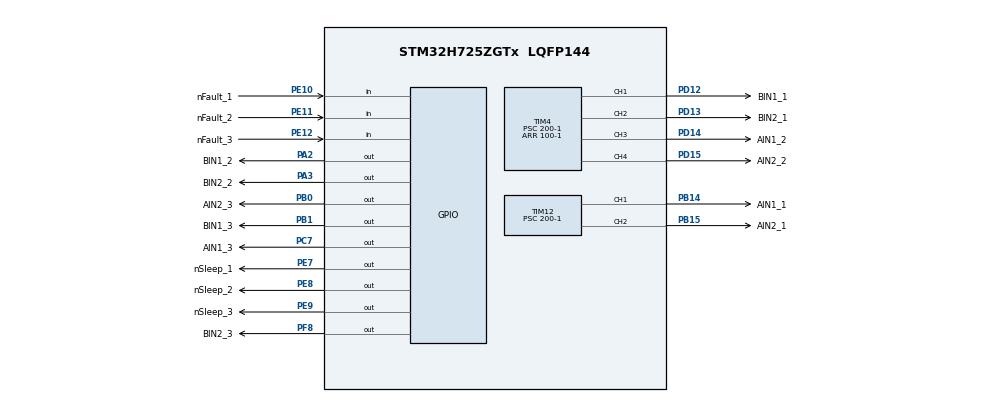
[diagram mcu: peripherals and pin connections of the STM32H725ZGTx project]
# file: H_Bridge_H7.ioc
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Mcu.Family=STM32H7
Mcu.Name=STM32H725ZGTx
Mcu.Package=LQFP144
NVIC.PriorityGroup=NVIC_PRIORITYGROUP_4
NVIC.TIM5_IRQn=true\:0\:0\:false\:false\:true\:true\:true\:true
PA2.GPIO_Label=BIN1_2
PA2.Signal=GPIO_Output
PA3.GPIO_Label=BIN2_2
PA3.Signal=GPIO_Output
PB0.GPIO_Label=AIN2_3
PB0.Signal=GPIO_Output
PB1.GPIO_Label=BIN1_3
PB1.Signal=GPIO_Output
PB14.GPIO_Label=AIN1_1
PB14.Signal=S_TIM12_CH1
PB15.GPIO_Label=AIN2_1
PB15.Signal=S_TIM12_CH2
PC7.GPIO_Label=AIN1_3
PC7.Signal=GPIO_Output
PD12.GPIO_Label=BIN1_1
PD12.Signal=S_TIM4_CH1
PD13.GPIO_Label=BIN2_1
PD13.Signal=S_TIM4_CH2
PD14.GPIO_Label=AIN1_2
PD14.Signal=S_TIM4_CH3
PD15.GPIO_Label=AIN2_2
PD15.Signal=S_TIM4_CH4
PE10.GPIO_Label=nFault_1
PE10.Signal=GPIO_Input
PE11.GPIO_Label=nFault_2
PE11.Signal=GPIO_Input
PE12.GPIO_Label=nFault_3
PE12.Signal=GPIO_Input
PE7.GPIO_Label=nSleep_1
PE7.Signal=GPIO_Output
PE8.GPIO_Label=nSleep_2
PE8.Signal=GPIO_Output
PE9.GPIO_Label=nSleep_3
PE9.Signal=GPIO_Output
PF8.GPIO_Label=BIN2_3
PF8.Signal=GPIO_Output
PH0-OSC_IN.Mode=HSE-External-Oscillator
PH0-OSC_IN.Signal=RCC_OSC_IN
PH1-OSC_OUT.Mode=HSE-External-Oscillator
PH1-OSC_OUT.Signal=RCC_OSC_OUT
ProjectManager.HeapSize=0x200
ProjectManager.StackSize=0x400
ProjectManager.TargetToolchain=STM32CubeIDE
RCC.ADCFreq_Value=50390625
RCC.APB1Freq_Value=100000000
RCC.APB2Freq_Value=100000000
RCC.APB3Freq_Value=100000000
RCC.APB4Freq_Value=100000000
RCC.CortexFreq_Value=200000000
RCC.D1PPRE=RCC_APB3_DIV2
RCC.D2PPRE1=RCC_APB1_DIV2
RCC.D2PPRE2=RCC_APB2_DIV2
RCC.D3PPRE=RCC_APB4_DIV2
RCC.DIVM1=2
RCC.DIVN1=16
RCC.DIVP1=1
RCC.HCLKFreq_Value=200000000
RCC.PLL2FRACN=0
RCC.PLL3FRACN=0
RCC.PLLFRACN=0
RCC.PLLSourceVirtual=RCC_PLLSOURCE_HSE
RCC.SYSCLKFreq_VALUE=200000000
RCC.SYSCLKSource=RCC_SYSCLKSOURCE_PLLCLK
RCC.USBFreq_Value=100000000
SH.S_TIM12_CH1.0=TIM12_CH1,PWM Generation1 CH1
SH.S_TIM12_CH2.0=TIM12_CH2,PWM Generation2 CH2
SH.S_TIM4_CH1.0=TIM4_CH1,PWM Generation1 CH1
SH.S_TIM4_CH2.0=TIM4_CH2,PWM Generation2 CH2
SH.S_TIM4_CH3.0=TIM4_CH3,PWM Generation3 CH3
SH.S_TIM4_CH4.0=TIM4_CH4,PWM Generation4 CH4
TIM12.Channel-PWM\ Generation1\ CH1=TIM_CHANNEL_1
TIM12.Channel-PWM\ Generation2\ CH2=TIM_CHANNEL_2
TIM12.Period=100-1
TIM12.Prescaler=200-1
TIM4.Channel-PWM\ Generation1\ CH1=TIM_CHANNEL_1
TIM4.Channel-PWM\ Generation2\ CH2=TIM_CHANNEL_2
TIM4.Channel-PWM\ Generation3\ CH3=TIM_CHANNEL_3
TIM4.Channel-PWM\ Generation4\ CH4=TIM_CHANNEL_4
TIM4.Period=100-1
TIM4.Prescaler=200-1
TIM5.Period=1-1
TIM5.Prescaler=4000-1
VP_TIM12_VS_ClockSourceINT.Mode=Internal
VP_TIM4_VS_ClockSourceINT.Mode=Internal
VP_TIM5_VS_ClockSourceINT.Mode=Internal
board=custom

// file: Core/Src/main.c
/* USER CODE BEGIN Header */
/**
  ******************************************************************************
  * @file           : main.c
  * @brief          : Main program body
  ******************************************************************************
  * @attention
  *
  * Copyright (c) 2024 STMicroelectronics.
  * All rights reserved.
  *
  * This software is licensed under terms that can be found in the LICENSE file
  * in the root directory of this software component.
  * If no LICENSE file comes with this software, it is provided AS-IS.
  *
  ******************************************************************************
  */
/* USER CODE END Header */
#include "main.h"

/* USER CODE BEGIN Includes */
#include "hbridge.h"
/* USER CODE END Includes */

TIM_HandleTypeDef htim4;
TIM_HandleTypeDef htim5;
TIM_HandleTypeDef htim12;

void SystemClock_Config(void);
static void MX_GPIO_Init(void);
static void MX_TIM4_Init(void);
static void MX_TIM12_Init(void);
static void MX_TIM5_Init(void);

int main(void)
{

  /* MCU Configuration--------------------------------------------------------*/

  /* Reset of all peripherals, Initializes the Flash interface and the Systick. */
  HAL_Init();

  /* Configure the system clock */
  SystemClock_Config();

  /* Initialize all configured peripherals */
  MX_GPIO_Init();
  MX_TIM4_Init();
  MX_TIM12_Init();
  MX_TIM5_Init();

  /* Infinite loop */
  while (1)
  {

  }
}

void SystemClock_Config(void)
{
  RCC_OscInitTypeDef RCC_OscInitStruct = {0};
  RCC_ClkInitTypeDef RCC_ClkInitStruct = {0};

  /** Supply configuration update enable
  */
  HAL_PWREx_ConfigSupply(PWR_DIRECT_SMPS_SUPPLY);

  /** Configure the main internal regulator output voltage
  */
  __HAL_PWR_VOLTAGESCALING_CONFIG(PWR_REGULATOR_VOLTAGE_SCALE2);

  while(!__HAL_PWR_GET_FLAG(PWR_FLAG_VOSRDY)) {}

  /** Initializes the RCC Oscillators according to the specified parameters
  * in the RCC_OscInitTypeDef structure.
  */
  RCC_OscInitStruct.OscillatorType = RCC_OSCILLATORTYPE_HSE;
  RCC_OscInitStruct.HSEState = RCC_HSE_ON;
  RCC_OscInitStruct.PLL.PLLState = RCC_PLL_ON;
  RCC_OscInitStruct.PLL.PLLSource = RCC_PLLSOURCE_HSE;
  RCC_OscInitStruct.PLL.PLLM = 2;
  RCC_OscInitStruct.PLL.PLLN = 16;
  RCC_OscInitStruct.PLL.PLLP = 1;
  RCC_OscInitStruct.PLL.PLLQ = 2;
  RCC_OscInitStruct.PLL.PLLR = 2;
  RCC_OscInitStruct.PLL.PLLRGE = RCC_PLL1VCIRANGE_3;
  RCC_OscInitStruct.PLL.PLLVCOSEL = RCC_PLL1VCOWIDE;
  RCC_OscInitStruct.PLL.PLLFRACN = 0;
  if (HAL_RCC_OscConfig(&RCC_OscInitStruct) != HAL_OK)
  {
    Error_Handler();
  }

  /** Initializes the CPU, AHB and APB buses clocks
  */
  RCC_ClkInitStruct.ClockType = RCC_CLOCKTYPE_HCLK|RCC_CLOCKTYPE_SYSCLK
                              |RCC_CLOCKTYPE_PCLK1|RCC_CLOCKTYPE_PCLK2
                              |RCC_CLOCKTYPE_D3PCLK1|RCC_CLOCKTYPE_D1PCLK1;
  RCC_ClkInitStruct.SYSCLKSource = RCC_SYSCLKSOURCE_PLLCLK;
  RCC_ClkInitStruct.SYSCLKDivider = RCC_SYSCLK_DIV1;
  RCC_ClkInitStruct.AHBCLKDivider = RCC_HCLK_DIV1;
  RCC_ClkInitStruct.APB3CLKDivider = RCC_APB3_DIV2;
  RCC_ClkInitStruct.APB1CLKDivider = RCC_APB1_DIV2;
  RCC_ClkInitStruct.APB2CLKDivider = RCC_APB2_DIV2;
  RCC_ClkInitStruct.APB4CLKDivider = RCC_APB4_DIV2;

  if (HAL_RCC_ClockConfig(&RCC_ClkInitStruct, FLASH_LATENCY_0) != HAL_OK)
  {
    Error_Handler();
  }
}

static void MX_TIM4_Init(void)
{

  TIM_ClockConfigTypeDef sClockSourceConfig = {0};
  TIM_MasterConfigTypeDef sMasterConfig = {0};
  TIM_OC_InitTypeDef sConfigOC = {0};

  htim4.Instance = TIM4;
  htim4.Init.Prescaler = 200-1;
  htim4.Init.CounterMode = TIM_COUNTERMODE_UP;
  htim4.Init.Period = 100-1;
  htim4.Init.ClockDivision = TIM_CLOCKDIVISION_DIV1;
  htim4.Init.AutoReloadPreload = TIM_AUTORELOAD_PRELOAD_DISABLE;
  if (HAL_TIM_Base_Init(&htim4) != HAL_OK)
  {
    Error_Handler();
  }
  sClockSourceConfig.ClockSource = TIM_CLOCKSOURCE_INTERNAL;
  if (HAL_TIM_ConfigClockSource(&htim4, &sClockSourceConfig) != HAL_OK)
  {
    Error_Handler();
  }
  if (HAL_TIM_PWM_Init(&htim4) != HAL_OK)
  {
    Error_Handler();
  }
  sMasterConfig.MasterOutputTrigger = TIM_TRGO_RESET;
  sMasterConfig.MasterSlaveMode = TIM_MASTERSLAVEMODE_DISABLE;
  if (HAL_TIMEx_MasterConfigSynchronization(&htim4, &sMasterConfig) != HAL_OK)
  {
    Error_Handler();
  }
  sConfigOC.OCMode = TIM_OCMODE_PWM1;
  sConfigOC.Pulse = 0;
  sConfigOC.OCPolarity = TIM_OCPOLARITY_HIGH;
  sConfigOC.OCFastMode = TIM_OCFAST_DISABLE;
  if (HAL_TIM_PWM_ConfigChannel(&htim4, &sConfigOC, TIM_CHANNEL_1) != HAL_OK)
  {
    Error_Handler();
  }
  if (HAL_TIM_PWM_ConfigChannel(&htim4, &sConfigOC, TIM_CHANNEL_2) != HAL_OK)
  {
    Error_Handler();
  }
  if (HAL_TIM_PWM_ConfigChannel(&htim4, &sConfigOC, TIM_CHANNEL_3) != HAL_OK)
  {
    Error_Handler();
  }
  if (HAL_TIM_PWM_ConfigChannel(&htim4, &sConfigOC, TIM_CHANNEL_4) != HAL_OK)
  {
    Error_Handler();
  }
  HAL_TIM_MspPostInit(&htim4);

}

static void MX_TIM5_Init(void)
{

  TIM_ClockConfigTypeDef sClockSourceConfig = {0};
  TIM_MasterConfigTypeDef sMasterConfig = {0};

  htim5.Instance = TIM5;
  htim5.Init.Prescaler = 4000-1;
  htim5.Init.CounterMode = TIM_COUNTERMODE_UP;
  htim5.Init.Period = 1-1;
  htim5.Init.ClockDivision = TIM_CLOCKDIVISION_DIV1;
  htim5.Init.AutoReloadPreload = TIM_AUTORELOAD_PRELOAD_DISABLE;
  if (HAL_TIM_Base_Init(&htim5) != HAL_OK)
  {
    Error_Handler();
  }
  sClockSourceConfig.ClockSource = TIM_CLOCKSOURCE_INTERNAL;
  if (HAL_TIM_ConfigClockSource(&htim5, &sClockSourceConfig) != HAL_OK)
  {
    Error_Handler();
  }
  sMasterConfig.MasterOutputTrigger = TIM_TRGO_RESET;
  sMasterConfig.MasterSlaveMode = TIM_MASTERSLAVEMODE_DISABLE;
  if (HAL_TIMEx_MasterConfigSynchronization(&htim5, &sMasterConfig) != HAL_OK)
  {
    Error_Handler();
  }

}

static void MX_TIM12_Init(void)
{

  TIM_ClockConfigTypeDef sClockSourceConfig = {0};
  TIM_MasterConfigTypeDef sMasterConfig = {0};
  TIM_OC_InitTypeDef sConfigOC = {0};

  htim12.Instance = TIM12;
  htim12.Init.Prescaler = 200-1;
  htim12.Init.CounterMode = TIM_COUNTERMODE_UP;
  htim12.Init.Period = 100-1;
  htim12.Init.ClockDivision = TIM_CLOCKDIVISION_DIV1;
  htim12.Init.AutoReloadPreload = TIM_AUTORELOAD_PRELOAD_DISABLE;
  if (HAL_TIM_Base_Init(&htim12) != HAL_OK)
  {
    Error_Handler();
  }
  sClockSourceConfig.ClockSource = TIM_CLOCKSOURCE_INTERNAL;
  if (HAL_TIM_ConfigClockSource(&htim12, &sClockSourceConfig) != HAL_OK)
  {
    Error_Handler();
  }
  if (HAL_TIM_PWM_Init(&htim12) != HAL_OK)
  {
    Error_Handler();
  }
  sMasterConfig.MasterOutputTrigger = TIM_TRGO_RESET;
  sMasterConfig.MasterSlaveMode = TIM_MASTERSLAVEMODE_DISABLE;
  if (HAL_TIMEx_MasterConfigSynchronization(&htim12, &sMasterConfig) != HAL_OK)
  {
    Error_Handler();
  }
  sConfigOC.OCMode = TIM_OCMODE_PWM1;
  sConfigOC.Pulse = 0;
  sConfigOC.OCPolarity = TIM_OCPOLARITY_HIGH;
  sConfigOC.OCFastMode = TIM_OCFAST_DISABLE;
  if (HAL_TIM_PWM_ConfigChannel(&htim12, &sConfigOC, TIM_CHANNEL_1) != HAL_OK)
  {
    Error_Handler();
  }
  if (HAL_TIM_PWM_ConfigChannel(&htim12, &sConfigOC, TIM_CHANNEL_2) != HAL_OK)
  {
    Error_Handler();
  }
  HAL_TIM_MspPostInit(&htim12);

}

static void MX_GPIO_Init(void)
{
  GPIO_InitTypeDef GPIO_InitStruct = {0};

  /* GPIO Ports Clock Enable */
  __HAL_RCC_GPIOF_CLK_ENABLE();
  __HAL_RCC_GPIOH_CLK_ENABLE();
  __HAL_RCC_GPIOA_CLK_ENABLE();
  __HAL_RCC_GPIOB_CLK_ENABLE();
  __HAL_RCC_GPIOE_CLK_ENABLE();
  __HAL_RCC_GPIOD_CLK_ENABLE();
  __HAL_RCC_GPIOC_CLK_ENABLE();

  /*Configure GPIO pin Output Level */
  HAL_GPIO_WritePin(BIN2_3_GPIO_Port, BIN2_3_Pin, GPIO_PIN_RESET);

  /*Configure GPIO pin Output Level */
  HAL_GPIO_WritePin(GPIOA, BIN1_2_Pin|BIN2_2_Pin, GPIO_PIN_RESET);

  /*Configure GPIO pin Output Level */
  HAL_GPIO_WritePin(GPIOB, AIN2_3_Pin|BIN1_3_Pin, GPIO_PIN_RESET);

  /*Configure GPIO pin Output Level */
  HAL_GPIO_WritePin(GPIOE, nSleep_1_Pin|nSleep_2_Pin|nSleep_3_Pin, GPIO_PIN_RESET);

  /*Configure GPIO pin Output Level */
  HAL_GPIO_WritePin(AIN1_3_GPIO_Port, AIN1_3_Pin, GPIO_PIN_RESET);

  /*Configure GPIO pin : BIN2_3_Pin */
  GPIO_InitStruct.Pin = BIN2_3_Pin;
  GPIO_InitStruct.Mode = GPIO_MODE_OUTPUT_PP;
  GPIO_InitStruct.Pull = GPIO_NOPULL;
  GPIO_InitStruct.Speed = GPIO_SPEED_FREQ_LOW;
  HAL_GPIO_Init(BIN2_3_GPIO_Port, &GPIO_InitStruct);

  /*Configure GPIO pins : BIN1_2_Pin BIN2_2_Pin */
  GPIO_InitStruct.Pin = BIN1_2_Pin|BIN2_2_Pin;
  GPIO_InitStruct.Mode = GPIO_MODE_OUTPUT_PP;
  GPIO_InitStruct.Pull = GPIO_NOPULL;
  GPIO_InitStruct.Speed = GPIO_SPEED_FREQ_LOW;
  HAL_GPIO_Init(GPIOA, &GPIO_InitStruct);

  /*Configure GPIO pins : AIN2_3_Pin BIN1_3_Pin */
  GPIO_InitStruct.Pin = AIN2_3_Pin|BIN1_3_Pin;
  GPIO_InitStruct.Mode = GPIO_MODE_OUTPUT_PP;
  GPIO_InitStruct.Pull = GPIO_NOPULL;
  GPIO_InitStruct.Speed = GPIO_SPEED_FREQ_LOW;
  HAL_GPIO_Init(GPIOB, &GPIO_InitStruct);

  /*Configure GPIO pins : nSleep_1_Pin nSleep_2_Pin nSleep_3_Pin */
  GPIO_InitStruct.Pin = nSleep_1_Pin|nSleep_2_Pin|nSleep_3_Pin;
  GPIO_InitStruct.Mode = GPIO_MODE_OUTPUT_PP;
  GPIO_InitStruct.Pull = GPIO_NOPULL;
  GPIO_InitStruct.Speed = GPIO_SPEED_FREQ_LOW;
  HAL_GPIO_Init(GPIOE, &GPIO_InitStruct);

  /*Configure GPIO pins : nFault_1_Pin nFault_2_Pin nFault_3_Pin */
  GPIO_InitStruct.Pin = nFault_1_Pin|nFault_2_Pin|nFault_3_Pin;
  GPIO_InitStruct.Mode = GPIO_MODE_INPUT;
  GPIO_InitStruct.Pull = GPIO_NOPULL;
  HAL_GPIO_Init(GPIOE, &GPIO_InitStruct);

  /*Configure GPIO pin : AIN1_3_Pin */
  GPIO_InitStruct.Pin = AIN1_3_Pin;
  GPIO_InitStruct.Mode = GPIO_MODE_OUTPUT_PP;
  GPIO_InitStruct.Pull = GPIO_NOPULL;
  GPIO_InitStruct.Speed = GPIO_SPEED_FREQ_LOW;
  HAL_GPIO_Init(AIN1_3_GPIO_Port, &GPIO_InitStruct);

}

void Error_Handler(void)
{
  __disable_irq();
  while (1)
  {
  }
}
